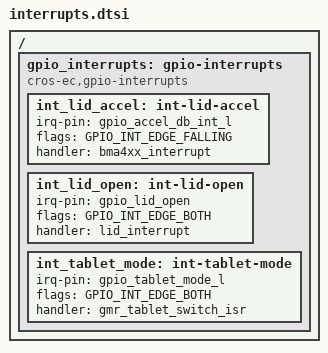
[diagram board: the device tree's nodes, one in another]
/* Copyright 2025 The ChromiumOS Authors
 * Use of this source code is governed by a BSD-style license that can be
 * found in the LICENSE file.
 */

/ {
	gpio_interrupts: gpio-interrupts {
		compatible = "cros-ec,gpio-interrupts";

		int_lid_accel: int-lid-accel {
			irq-pin = <&gpio_accel_db_int_l>;
			flags = <GPIO_INT_EDGE_FALLING>;
			handler = "bma4xx_interrupt";
		};
		int_lid_open: int-lid-open {
			irq-pin = <&gpio_lid_open>;
			flags = <GPIO_INT_EDGE_BOTH>;
			handler = "lid_interrupt";
		};
		int_tablet_mode: int-tablet-mode {
			irq-pin = <&gpio_tablet_mode_l>;
			flags = <GPIO_INT_EDGE_BOTH>;
			handler = "gmr_tablet_switch_isr";
		};
	};
};
